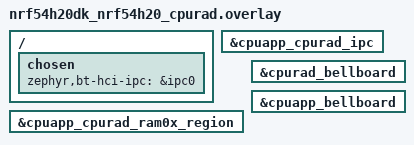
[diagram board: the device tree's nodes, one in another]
/*
 * Copyright 2024 Nordic Semiconductor ASA
 *
 * SPDX-License-Identifier: Apache-2.0
 */

/ {
	chosen {
		zephyr,bt-hci-ipc = &ipc0;
	};
};

ipc0: &cpuapp_cpurad_ipc {
	status = "okay";
};

&cpuapp_cpurad_ram0x_region {
	status = "okay";
};

&cpurad_bellboard {
	status = "okay";
};

&cpuapp_bellboard {
	status = "okay";
};
